# ATmega16U4 device description
Architecture: AVR8; Family: megaAVR
Registers are 8-bit, access not given, no defined reset value unless marked. A register's access mark holds for its fields unless they carry their own. Offsets are from the block's base; [hi:lo] are bit positions.

## TC3 (TC16 module) — Timer/Counter, 16-bit
Instances: TC3 0x00
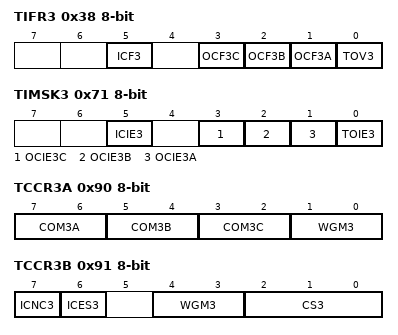
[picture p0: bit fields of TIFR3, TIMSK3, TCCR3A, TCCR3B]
0x38 TIFR3 — Timer/Counter3 Interrupt Flag register
  [5] ICF3 — Input Capture Flag 3
  [3] OCF3C — Output Compare Flag 3C
  [2] OCF3B — Output Compare Flag 3B
  [1] OCF3A — Output Compare Flag 3A
  [0] TOV3 — Timer/Counter3 Overflow Flag
0x71 TIMSK3 — Timer/Counter3 Interrupt Mask Register
  [5] ICIE3 — Timer/Counter3 Input Capture Interrupt Enable
  [3] OCIE3C — Timer/Counter3 Output Compare C Match Interrupt Enable
  [2] OCIE3B — Timer/Counter3 Output Compare B Match Interrupt Enable
  [1] OCIE3A — Timer/Counter3 Output Compare A Match Interrupt Enable
  [0] TOIE3 — Timer/Counter3 Overflow Interrupt Enable
0x90 TCCR3A — Timer/Counter3 Control Register A
  [7:6] COM3A — Compare Output Mode 1A, bits
  [5:4] COM3B — Compare Output Mode 3B, bits
  [3:2] COM3C — Compare Output Mode 3C, bits
  [1:0] WGM3 — Waveform Generation Mode
0x91 TCCR3B — Timer/Counter3 Control Register B
  [7] ICNC3 — Input Capture 3 Noise Canceler
  [6] ICES3 — Input Capture 3 Edge Select
  [4:3] WGM3 (bit 2 of the value upward) — Waveform Generation Mode
  [2:0] CS3 — Prescaler source of Timer/Counter 3
    0=No Clock Source (Stopped); 1=Running, No Prescaling; 2=Running, CLK/8; 3=Running, CLK/64; 4=Running, CLK/256; 5=Running, CLK/1024; 6=Running, ExtClk Tx Falling Edge; 7=Running, ExtClk Tx Rising Edge
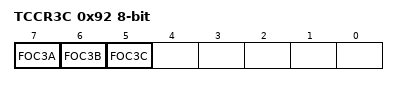
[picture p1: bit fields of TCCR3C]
0x92 TCCR3C — Timer/Counter 3 Control Register C
  [7] FOC3A — Force Output Compare 3A
  [6] FOC3B — Force Output Compare 3B
  [5] FOC3C — Force Output Compare 3C
0x94 TCNT3 16-bit — Timer/Counter3 Bytes
  [15:0] TCNT3 — Timer/Counter3 bits
0x96 ICR3 16-bit — Timer/Counter3 Input Capture Register Bytes
  [15:0] ICR3 — Timer/Counter3 Input Capture bits
0x98 OCR3A 16-bit — Timer/Counter3 Output Compare Register A Bytes
  [15:0] OCR3A — Timer/Counter3 Output Compare A bits
0x9A OCR3B 16-bit — Timer/Counter3 Output Compare Register B Bytes
  [15:0] OCR3B — Timer/Counter3 Output Compare B bits
0x9C OCR3C 16-bit — Timer/Counter3 Output Compare Register C Bytes
  [15:0] OCR3C — Timer/Counter3 Output Compare C bits

## TC1 (TC16 module) — Timer/Counter, 16-bit
Instances: TC1 0x00
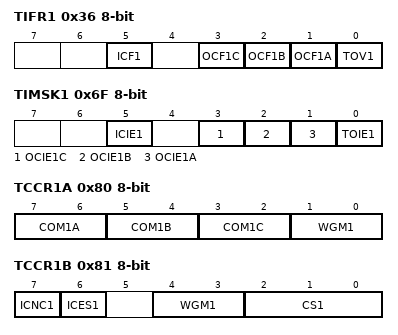
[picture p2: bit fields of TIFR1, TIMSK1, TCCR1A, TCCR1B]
0x36 TIFR1 — Timer/Counter1 Interrupt Flag register
  [5] ICF1 — Input Capture Flag 1
  [3] OCF1C — Output Compare Flag 1C
  [2] OCF1B — Output Compare Flag 1B
  [1] OCF1A — Output Compare Flag 1A
  [0] TOV1 — Timer/Counter1 Overflow Flag
0x6F TIMSK1 — Timer/Counter1 Interrupt Mask Register
  [5] ICIE1 — Timer/Counter1 Input Capture Interrupt Enable
  [3] OCIE1C — Timer/Counter1 Output Compare C Match Interrupt Enable
  [2] OCIE1B — Timer/Counter1 Output Compare B Match Interrupt Enable
  [1] OCIE1A — Timer/Counter1 Output Compare A Match Interrupt Enable
  [0] TOIE1 — Timer/Counter1 Overflow Interrupt Enable
0x80 TCCR1A — Timer/Counter1 Control Register A
  [7:6] COM1A — Compare Output Mode 1A, bits
  [5:4] COM1B — Compare Output Mode 1B, bits
  [3:2] COM1C — Compare Output Mode 1C, bits
  [1:0] WGM1 — Waveform Generation Mode
0x81 TCCR1B — Timer/Counter1 Control Register B
  [7] ICNC1 — Input Capture 1 Noise Canceler
  [6] ICES1 — Input Capture 1 Edge Select
  [4:3] WGM1 (bit 2 of the value upward) — Waveform Generation Mode
  [2:0] CS1 — Prescaler source of Timer/Counter 1
    0=No Clock Source (Stopped); 1=Running, No Prescaling; 2=Running, CLK/8; 3=Running, CLK/64; 4=Running, CLK/256; 5=Running, CLK/1024; 6=Running, ExtClk Tx Falling Edge; 7=Running, ExtClk Tx Rising Edge
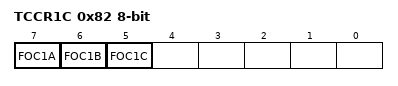
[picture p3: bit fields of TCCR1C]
0x82 TCCR1C — Timer/Counter 1 Control Register C
  [7] FOC1A — Force Output Compare 1A
  [6] FOC1B — Force Output Compare 1B
  [5] FOC1C — Force Output Compare 1C
0x84 TCNT1 16-bit — Timer/Counter1 Bytes
  [15:0] TCNT1 — Timer/Counter1 bits
0x86 ICR1 16-bit — Timer/Counter1 Input Capture Register Bytes
  [15:0] ICR1 — Timer/Counter1 Input Capture bits
0x88 OCR1A 16-bit — Timer/Counter1 Output Compare Register A Bytes
  [15:0] OCR1A — Timer/Counter1 Output Compare A bits
0x8A OCR1B 16-bit — Timer/Counter1 Output Compare Register B Bytes
  [15:0] OCR1B — Timer/Counter1 Output Compare B bits
0x8C OCR1C 16-bit — Timer/Counter1 Output Compare Register C Bytes
  [15:0] OCR1C — Timer/Counter1 Output Compare C bits
